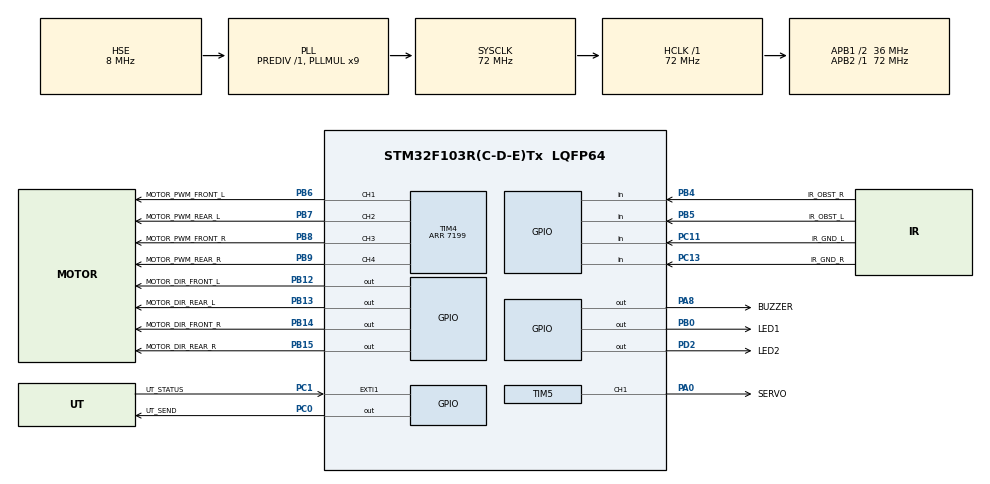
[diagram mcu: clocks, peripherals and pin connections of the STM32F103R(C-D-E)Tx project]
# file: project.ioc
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Mcu.Family=STM32F1
Mcu.Name=STM32F103R(C-D-E)Tx
Mcu.Package=LQFP64
NVIC.EXTI1_IRQn=true\:2\:2\:true\:false\:true\:true\:true\:true
NVIC.PriorityGroup=NVIC_PRIORITYGROUP_2
PA0-WKUP.GPIO_Label=SERVO
PA0-WKUP.GPIO_Speed=GPIO_SPEED_FREQ_HIGH
PA0-WKUP.Signal=S_TIM5_CH1
PA13.Mode=Serial_Wire
PA13.Signal=SYS_JTMS-SWDIO
PA14.Mode=Serial_Wire
PA14.Signal=SYS_JTCK-SWCLK
PA8.GPIO_Label=BUZZER
PA8.GPIO_Speed=GPIO_SPEED_FREQ_HIGH
PA8.PinState=GPIO_PIN_SET
PA8.Signal=GPIO_Output
PB0.GPIO_Label=LED1
PB0.GPIO_Speed=GPIO_SPEED_FREQ_HIGH
PB0.PinState=GPIO_PIN_SET
PB0.Signal=GPIO_Output
PB12.GPIO_Label=MOTOR_DIR_FRONT_L
PB12.GPIO_Speed=GPIO_SPEED_FREQ_HIGH
PB12.Signal=GPIO_Output
PB13.GPIO_Label=MOTOR_DIR_REAR_L
PB13.GPIO_Speed=GPIO_SPEED_FREQ_HIGH
PB13.Signal=GPIO_Output
PB14.GPIO_Label=MOTOR_DIR_FRONT_R
PB14.GPIO_Speed=GPIO_SPEED_FREQ_HIGH
PB14.Signal=GPIO_Output
PB15.GPIO_Label=MOTOR_DIR_REAR_R
PB15.GPIO_Speed=GPIO_SPEED_FREQ_HIGH
PB15.Signal=GPIO_Output
PB4.GPIO_Label=IR_OBST_R
PB4.GPIO_PuPd=GPIO_PULLUP
PB4.Signal=GPIO_Input
PB5.GPIO_Label=IR_OBST_L
PB5.GPIO_PuPd=GPIO_PULLUP
PB5.Signal=GPIO_Input
PB6.GPIO_Label=MOTOR_PWM_FRONT_L
PB6.GPIO_Speed=GPIO_SPEED_FREQ_HIGH
PB6.Signal=S_TIM4_CH1
PB7.GPIO_Label=MOTOR_PWM_REAR_L
PB7.GPIO_Speed=GPIO_SPEED_FREQ_HIGH
PB7.Signal=S_TIM4_CH2
PB8.GPIO_Label=MOTOR_PWM_FRONT_R
PB8.GPIO_Speed=GPIO_SPEED_FREQ_HIGH
PB8.Signal=S_TIM4_CH3
PB9.GPIO_Label=MOTOR_PWM_REAR_R
PB9.GPIO_Speed=GPIO_SPEED_FREQ_HIGH
PB9.Signal=S_TIM4_CH4
PC0.GPIO_Label=UT_SEND
PC0.GPIO_Speed=GPIO_SPEED_FREQ_HIGH
PC0.Signal=GPIO_Output
PC1.GPIO_Label=UT_STATUS
PC1.GPIO_PuPd=GPIO_PULLDOWN
PC1.Signal=GPXTI1
PC11.GPIO_Label=IR_GND_L
PC11.GPIO_PuPd=GPIO_PULLUP
PC11.Signal=GPIO_Input
PC13-TAMPER-RTC.GPIO_Label=IR_GND_R
PC13-TAMPER-RTC.GPIO_PuPd=GPIO_PULLUP
PC13-TAMPER-RTC.Signal=GPIO_Input
PD0-OSC_IN.Mode=HSE-External-Oscillator
PD0-OSC_IN.Signal=RCC_OSC_IN
PD1-OSC_OUT.Mode=HSE-External-Oscillator
PD1-OSC_OUT.Signal=RCC_OSC_OUT
PD2.GPIO_Label=LED2
PD2.GPIO_Speed=GPIO_SPEED_FREQ_HIGH
PD2.PinState=GPIO_PIN_SET
PD2.Signal=GPIO_Output
ProjectManager.HeapSize=0x200
ProjectManager.StackSize=0x400
ProjectManager.TargetToolchain=STM32CubeIDE
RCC.AHBFreq_Value=72000000
RCC.APB1CLKDivider=RCC_HCLK_DIV2
RCC.APB1Freq_Value=36000000
RCC.APB1TimFreq_Value=72000000
RCC.APB2Freq_Value=72000000
RCC.APB2TimFreq_Value=72000000
RCC.HCLKFreq_Value=72000000
RCC.PLLMUL=RCC_PLL_MUL9
RCC.PLLSourceVirtual=RCC_PLLSOURCE_HSE
RCC.SYSCLKFreq_VALUE=72000000
RCC.SYSCLKSource=RCC_SYSCLKSOURCE_PLLCLK
RCC.USBFreq_Value=72000000
SH.S_TIM4_CH1.0=TIM4_CH1,PWM Generation1 CH1
SH.S_TIM4_CH2.0=TIM4_CH2,PWM Generation2 CH2
SH.S_TIM4_CH3.0=TIM4_CH3,PWM Generation3 CH3
SH.S_TIM4_CH4.0=TIM4_CH4,PWM Generation4 CH4
SH.S_TIM5_CH1.0=TIM5_CH1,PWM Generation1 CH1
TIM1.Prescaler=71
TIM2.Period=5000
TIM2.Prescaler=7199
TIM4.AutoReloadPreload=TIM_AUTORELOAD_PRELOAD_ENABLE
TIM4.Channel-PWM\ Generation1\ CH1=TIM_CHANNEL_1
TIM4.Channel-PWM\ Generation2\ CH2=TIM_CHANNEL_2
TIM4.Channel-PWM\ Generation3\ CH3=TIM_CHANNEL_3
TIM4.Channel-PWM\ Generation4\ CH4=TIM_CHANNEL_4
TIM4.OCMode_PWM-PWM\ Generation1\ CH1=TIM_OCMODE_PWM2
TIM4.OCMode_PWM-PWM\ Generation2\ CH2=TIM_OCMODE_PWM2
TIM4.OCMode_PWM-PWM\ Generation3\ CH3=TIM_OCMODE_PWM2
TIM4.OCMode_PWM-PWM\ Generation4\ CH4=TIM_OCMODE_PWM2
TIM4.Period=7199
TIM5.AutoReloadPreload=TIM_AUTORELOAD_PRELOAD_ENABLE
TIM5.Channel-PWM\ Generation1\ CH1=TIM_CHANNEL_1
TIM5.Channel-PWM\ Generation2\ No\ Output=TIM_CHANNEL_2
TIM5.OC2Preload_PWM=ENABLE
TIM5.Period=9999
TIM5.Prescaler=143
TIM5.TIM_MasterOutputTrigger=TIM_TRGO_RESET
VP_TIM1_VS_ClockSourceINT.Mode=Internal
VP_TIM2_VS_ClockSourceINT.Mode=Internal
VP_TIM4_VS_ClockSourceINT.Mode=Internal
VP_TIM5_VS_ClockSourceINT.Mode=Internal
VP_TIM5_VS_no_output2.Mode=PWM Generation2 No Output
board=custom

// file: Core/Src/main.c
/* USER CODE BEGIN Header */
/**
  ******************************************************************************
  * @file           : main.c
  * @brief          : Main program body
  ******************************************************************************
  * @attention
  *
  * Copyright (c) 2024 STMicroelectronics.
  * All rights reserved.
  *
  * This software is licensed under terms that can be found in the LICENSE file
  * in the root directory of this software component.
  * If no LICENSE file comes with this software, it is provided AS-IS.
  *
  ******************************************************************************
  */
/* USER CODE END Header */
#include "main.h"
#include "tim.h"
#include "gpio.h"

/* USER CODE BEGIN Includes */
//#include "myMotor.h"
#include "utils.h"
/* USER CODE END Includes */

void SystemClock_Config(void);

int main(void)
{

  /* MCU Configuration--------------------------------------------------------*/

  /* Reset of all peripherals, Initializes the Flash interface and the Systick. */
  HAL_Init();

  /* Configure the system clock */
  SystemClock_Config();

  /* Initialize all configured peripherals */
  MX_GPIO_Init();
  MX_TIM5_Init();
  MX_TIM2_Init();
  MX_TIM1_Init();
  MX_TIM4_Init();
  /* USER CODE BEGIN 2 */
//  myMotorInit();
  HAL_TIM_Base_Start(&htim1);
  HAL_TIM_PWM_Start(&htim4, TIM_CHANNEL_1);
  HAL_TIM_PWM_Start(&htim4, TIM_CHANNEL_2);
  HAL_TIM_PWM_Start(&htim4, TIM_CHANNEL_3);
  HAL_TIM_PWM_Start(&htim4, TIM_CHANNEL_4);
  HAL_TIM_PWM_Start(&htim5, TIM_CHANNEL_1);
  TURN_OFF_BUZZER;
  /* USER CODE END 2 */

  /* Infinite loop */
  while (1)
  {
	  myCarBrake(0);
	  HAL_Delay(500);
	  myCarRun(50, 0);
	  HAL_Delay(500);
  }
}

void SystemClock_Config(void)
{
  RCC_OscInitTypeDef RCC_OscInitStruct = {0};
  RCC_ClkInitTypeDef RCC_ClkInitStruct = {0};

  /** Initializes the RCC Oscillators according to the specified parameters
  * in the RCC_OscInitTypeDef structure.
  */
  RCC_OscInitStruct.OscillatorType = RCC_OSCILLATORTYPE_HSE;
  RCC_OscInitStruct.HSEState = RCC_HSE_ON;
  RCC_OscInitStruct.HSEPredivValue = RCC_HSE_PREDIV_DIV1;
  RCC_OscInitStruct.HSIState = RCC_HSI_ON;
  RCC_OscInitStruct.PLL.PLLState = RCC_PLL_ON;
  RCC_OscInitStruct.PLL.PLLSource = RCC_PLLSOURCE_HSE;
  RCC_OscInitStruct.PLL.PLLMUL = RCC_PLL_MUL9;
  if (HAL_RCC_OscConfig(&RCC_OscInitStruct) != HAL_OK)
  {
    Error_Handler();
  }

  /** Initializes the CPU, AHB and APB buses clocks
  */
  RCC_ClkInitStruct.ClockType = RCC_CLOCKTYPE_HCLK|RCC_CLOCKTYPE_SYSCLK
                              |RCC_CLOCKTYPE_PCLK1|RCC_CLOCKTYPE_PCLK2;
  RCC_ClkInitStruct.SYSCLKSource = RCC_SYSCLKSOURCE_PLLCLK;
  RCC_ClkInitStruct.AHBCLKDivider = RCC_SYSCLK_DIV1;
  RCC_ClkInitStruct.APB1CLKDivider = RCC_HCLK_DIV2;
  RCC_ClkInitStruct.APB2CLKDivider = RCC_HCLK_DIV1;

  if (HAL_RCC_ClockConfig(&RCC_ClkInitStruct, FLASH_LATENCY_2) != HAL_OK)
  {
    Error_Handler();
  }
}

void Error_Handler(void)
{
  __disable_irq();
  while (1)
  {
  }
}
